# STM32H563 register map
File version: 0.4
CPU: CM33 r0p0, little endian, MPU, FPU, 4 interrupt priority bits
Registers are 32-bit, read-write, reset 0x0 unless marked. A register's access mark holds for its fields unless they carry their own. Offsets are from the block's base; [hi:lo] are bit positions; {n}, {i} and the like mark numbered series.

## DCMI — Digital camera interface
Base 0x4202C000
Same registers: SEC_DCMI 0x5202C000
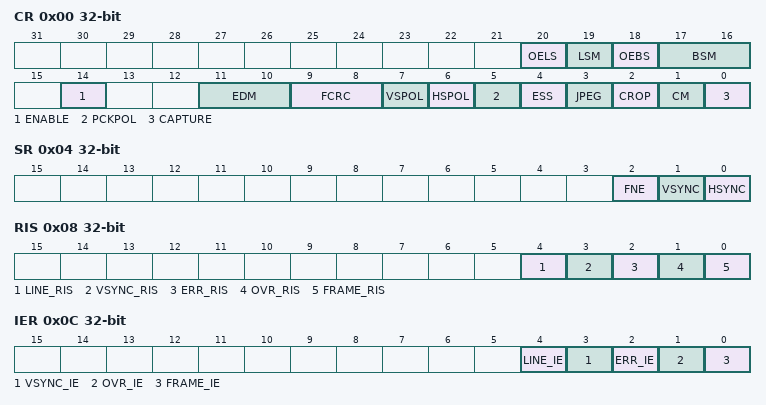
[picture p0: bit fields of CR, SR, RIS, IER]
0x00 CR — DCMI control register
  [20] OELS — Odd/Even Line Select (Line Select Start) This bit works in conjunction with the LSM field (LSM = 1).
  [19] LSM — Line Select mode
  [18] OEBS — Odd/Even Byte Select (Byte Select Start) This bit works in conjunction with BSM field (BSM ≠ 00).
  [17:16] BSM — Byte Select mode Note: This mode only works for EDM[1:0] = 00. For all other EDM values, this field must be programmed to the reset value.
  [14] ENABLE — DCMI enable Note: The DCMI configuration registers must be programmed correctly before enabling this bit.
  [11:10] EDM — Extended data mode
  [9:8] FCRC — Frame capture rate control These bits define the frequency of frame capture. They are meaningful only in Continuous grab mode. They are ignored in snapshot mode.
  [7] VSPOL — Vertical synchronization polarity This bit indicates the level on the DCMI_VSYNC pin when the data are not valid on the parallel interface.
  [6] HSPOL — Horizontal synchronization polarity This bit indicates the level on the DCMI_HSYNC pin when the data are not valid on the parallel interface.
  [5] PCKPOL — Pixel clock polarity This bit configures the capture edge of the pixel clock.
  [4] ESS — Embedded synchronization select Note: Valid only for 8-bit parallel data. HSPOL/VSPOL are ignored when the ESS bit is set. This bit is disabled in JPEG mode.
  [3] JPEG — JPEG format
  [2] CROP — Crop feature
  [1] CM — Capture mode
  [0] CAPTURE — Capture enable The camera interface waits for the first start of frame, then a DMA request is generated to transfer the received data into the destination memory. In snapshot mode, the CAPTURE bit is automatically cleared at the end of the first frame received. In continuous grab mode, if the software clears this bit while a capture is ongoing, the bit is effectively cleared after the frame end. Note: The DMA controller and all DCMI configuration registers must be programmed correctly before enabling this bit.
0x04 SR ro — DCMI status register
  [2] FNE — FIFO not empty This bit gives the status of the FIFO.
  [1] VSYNC — Vertical synchronization This bit gives the state of the DCMI_VSYNC pin with the correct programmed polarity. When embedded synchronization codes are used, the meaning of this bit is the following: In case of embedded synchronization, this bit is meaningful only if the CAPTURE bit in DCMI_CR is set.
  [0] HSYNC — Horizontal synchronization This bit gives the state of the DCMI_HSYNC pin with the correct programmed polarity. When embedded synchronization codes are used, the meaning of this bit is the following: In case of embedded synchronization, this bit is meaningful only if the CAPTURE bit in DCMI_CR is set.
0x08 RIS ro — DCMI raw interrupt status register
  [4] LINE_RIS — Line raw interrupt status This bit gets set when the DCMI_HSYNC signal changes from the inactive state to the active state. It goes high even if the line is not valid. In the case of embedded synchronization, this bit is set only if the CAPTURE bit in DCMI_CR is set. It is cleared by setting the LINE_ISC bit of the DCMI_ICR register.
  [3] VSYNC_RIS — DCMI_VSYNC raw interrupt status This bit is set when the DCMI_VSYNC signal changes from the inactive state to the active state. In the case of embedded synchronization, this bit is set only if the CAPTURE bit is set in DCMI_CR. It is cleared by setting the VSYNC_ISC bit of the DCMI_ICR register.
  [2] ERR_RIS — Synchronization error raw interrupt status This bit is valid only in the embedded synchronization mode. It is cleared by setting the ERR_ISC bit of the DCMI_ICR register. Note: This bit is available only in embedded synchronization mode.
  [1] OVR_RIS — Overrun raw interrupt status The bit is cleared by setting the OVR_ISC bit of the DCMI_ICR register.
  [0] FRAME_RIS — Capture complete raw interrupt status This bit is set when a frame or window has been captured. In case of a cropped window, this bit is set at the end of line of the last line in the crop. It is set even if the captured frame is empty (e.g. window cropped outside the frame). The bit is cleared by setting the FRAME_ISC bit of the DCMI_ICR register.
0x0C IER — DCMI interrupt enable register
  [4] LINE_IE — Line interrupt enable
  [3] VSYNC_IE — DCMI_VSYNC interrupt enable The active state of the DCMI_VSYNC signal is defined by the VSPOL bit.
  [2] ERR_IE — Synchronization error interrupt enable Note: This bit is available only in embedded synchronization mode.
  [1] OVR_IE — Overrun interrupt enable
  [0] FRAME_IE — Capture complete interrupt enable
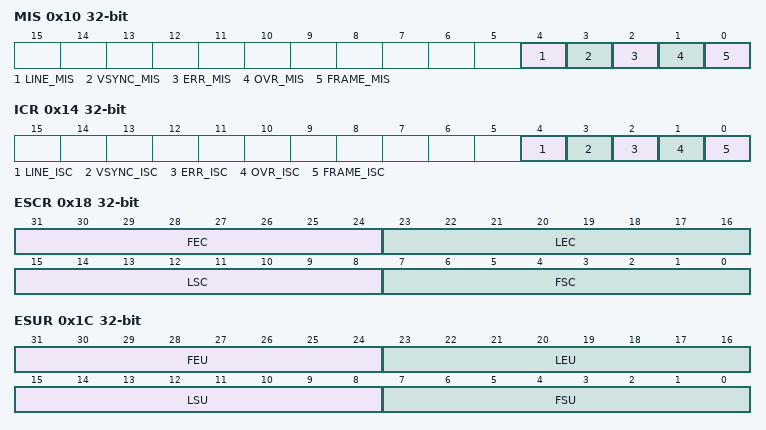
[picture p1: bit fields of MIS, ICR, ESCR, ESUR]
0x10 MIS ro — DCMI masked interrupt status register
  [4] LINE_MIS — Line masked interrupt status This bit gives the status of the masked line interrupt.
  [3] VSYNC_MIS — VSYNC masked interrupt status This bit gives the status of the masked VSYNC interrupt. The active state of the DCMI_VSYNC signal is defined by the VSPOL bit.
  [2] ERR_MIS — Synchronization error masked interrupt status This bit gives the status of the masked synchronization error interrupt. Note: This bit is available only in embedded synchronization mode.
  [1] OVR_MIS — Overrun masked interrupt status This bit gives the status of the masked overflow interrupt.
  [0] FRAME_MIS — Capture complete masked interrupt status This bit gives the status of the masked capture complete interrupt
0x14 ICR wo — DCMI interrupt clear register
  [4] LINE_ISC — line interrupt status clear Setting this bit clears the LINE_RIS flag in the DCMI_RIS register.
  [3] VSYNC_ISC — Vertical Synchronization interrupt status clear Setting this bit clears the VSYNC_RIS flag in the DCMI_RIS register.
  [2] ERR_ISC — Synchronization error interrupt status clear Setting this bit clears the ERR_RIS flag in the DCMI_RIS register. Note: This bit is available only in embedded synchronization mode.
  [1] OVR_ISC — Overrun interrupt status clear Setting this bit clears the OVR_RIS flag in the DCMI_RIS register.
  [0] FRAME_ISC — Capture complete interrupt status clear Setting this bit clears the FRAME_RIS flag in the DCMI_RIS register.
0x18 ESCR — DCMI embedded synchronization code register
  [31:24] FEC — Frame end delimiter code This byte specifies the code of the frame end delimiter. The code consists of 4 bytes in the form of 0xFF, 0x00, 0x00, FEC. If FEC is programmed to 0xFF, all the unused codes (0xFF0000XY) are interpreted as frame end delimiters.
  [23:16] LEC — Line end delimiter code This byte specifies the code of the line end delimiter. The code consists of 4 bytes in the form of 0xFF, 0x00, 0x00, LEC.
  [15:8] LSC — Line start delimiter code This byte specifies the code of the line start delimiter. The code consists of 4 bytes in the form of 0xFF, 0x00, 0x00, LSC.
  [7:0] FSC — Frame start delimiter code This byte specifies the code of the frame start delimiter. The code consists of 4 bytes in the form of 0xFF, 0x00, 0x00, FSC. If FSC is programmed to 0xFF, no frame start delimiter is detected. But, the first occurrence of LSC after an FEC code is interpreted as a start of frame delimiter.
0x1C ESUR — DCMI embedded synchronization unmask register
  [31:24] FEU — Frame end delimiter unmask This byte specifies the mask to be applied to the code of the frame end delimiter.
  [23:16] LEU — Line end delimiter unmask This byte specifies the mask to be applied to the code of the line end delimiter.
  [15:8] LSU — Line start delimiter unmask This byte specifies the mask to be applied to the code of the line start delimiter.
  [7:0] FSU — Frame start delimiter unmask This byte specifies the mask to be applied to the code of the frame start delimiter.
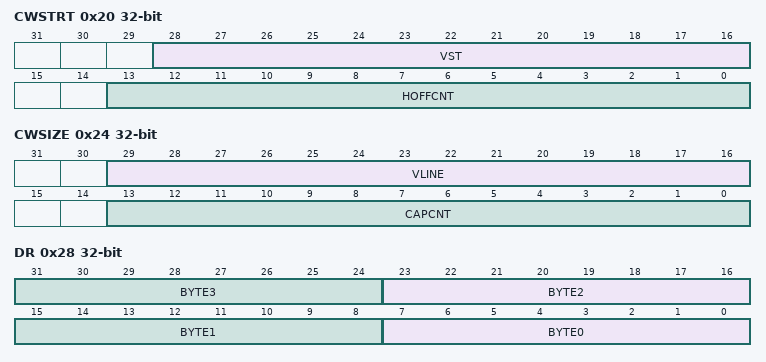
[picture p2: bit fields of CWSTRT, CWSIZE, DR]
0x20 CWSTRT — DCMI crop window start
  [28:16] VST — Vertical start line count The image capture starts with this line number. Previous line data are ignored. ....
  [13:0] HOFFCNT — Horizontal offset count This value gives the number of pixel clocks to count before starting a capture.
0x24 CWSIZE — DCMI crop window size
  [29:16] VLINE — Vertical line count This value gives the number of lines to be captured from the starting point. ....
  [13:0] CAPCNT — Capture count This value gives the number of pixel clocks to be captured from the starting point on the same line. It value must corresponds to word-aligned data for different widths of parallel interfaces. 0x0000 => 1 pixel 0x0001 => 2 pixels 0x0002 => 3 pixels ....
0x28 DR ro — DCMI data register
  [8n+7:8n] BYTE{n} (n=0..3) — Data byte {n}
